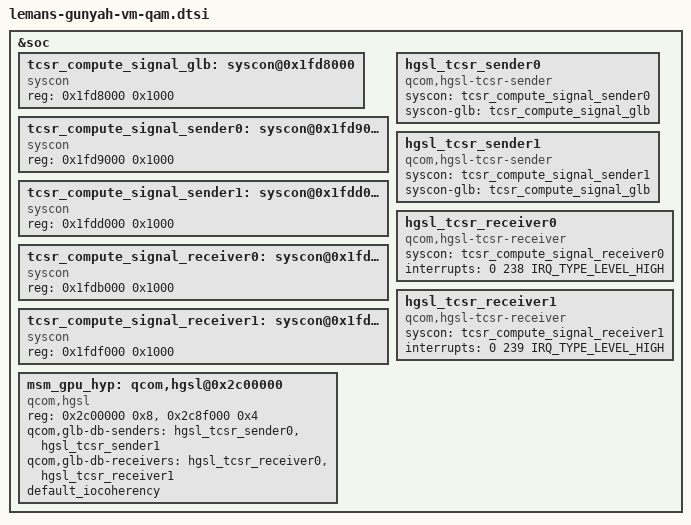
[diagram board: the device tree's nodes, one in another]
#include "lemans-gunyah-vm.dtsi"

&soc {
	tcsr_compute_signal_glb: syscon@0x1fd8000 {
		compatible = "syscon";
		reg = <0x1fd8000 0x1000>;
	};

	tcsr_compute_signal_sender0: syscon@0x1fd9000 {
		compatible = "syscon";
		reg = <0x1fd9000 0x1000>;
	};

	tcsr_compute_signal_sender1: syscon@0x1fdd000 {
		compatible = "syscon";
		reg = <0x1fdd000 0x1000>;
	};

	tcsr_compute_signal_receiver0: syscon@0x1fdb000 {
		compatible = "syscon";
		reg = <0x1fdb000 0x1000>;
	};

	tcsr_compute_signal_receiver1: syscon@0x1fdf000 {
		compatible = "syscon";
		reg = <0x1fdf000 0x1000>;
	};

	hgsl_tcsr_sender0: hgsl_tcsr_sender0 {
		compatible = "qcom,hgsl-tcsr-sender";
		syscon = <&tcsr_compute_signal_sender0>;
		syscon-glb = <&tcsr_compute_signal_glb>;
	};

	hgsl_tcsr_sender1: hgsl_tcsr_sender1 {
		compatible = "qcom,hgsl-tcsr-sender";
		syscon = <&tcsr_compute_signal_sender1>;
		syscon-glb = <&tcsr_compute_signal_glb>;
	};

	hgsl_tcsr_receiver0: hgsl_tcsr_receiver0 {
		compatible = "qcom,hgsl-tcsr-receiver";
		syscon = <&tcsr_compute_signal_receiver0>;
		interrupts = <0 238 IRQ_TYPE_LEVEL_HIGH>;
	};

	hgsl_tcsr_receiver1: hgsl_tcsr_receiver1 {
		compatible = "qcom,hgsl-tcsr-receiver";
		syscon = <&tcsr_compute_signal_receiver1>;
		interrupts = <0 239 IRQ_TYPE_LEVEL_HIGH>;
	};

	msm_gpu_hyp: qcom,hgsl@0x2c00000 {
		compatible = "qcom,hgsl";
		reg = <0x2c00000 0x8>, <0x2c8f000 0x4>;
		reg-names = "hgsl_reg_hwinf", "hgsl_reg_gmucx";

		qcom,glb-db-senders = <&hgsl_tcsr_sender0
					&hgsl_tcsr_sender1>;
		qcom,glb-db-receivers = <&hgsl_tcsr_receiver0
					&hgsl_tcsr_receiver1>;

		default_iocoherency;
	};
};
